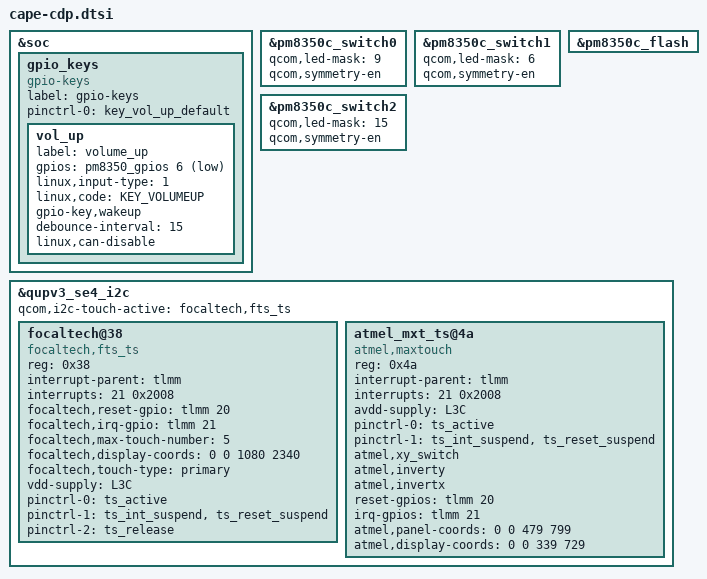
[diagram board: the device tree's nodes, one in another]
#include <dt-bindings/gpio/gpio.h>
#include <dt-bindings/input/input.h>

#include "cape-pmic-overlay.dtsi"

&soc {
	gpio_keys {
		compatible = "gpio-keys";
		label = "gpio-keys";

		pinctrl-names = "default";
		pinctrl-0 = <&key_vol_up_default>;

		vol_up {
			label = "volume_up";
			gpios = <&pm8350_gpios 6 GPIO_ACTIVE_LOW>;
			linux,input-type = <1>;
			linux,code = <KEY_VOLUMEUP>;
			gpio-key,wakeup;
			debounce-interval = <15>;
			linux,can-disable;
		};
	};
};

&pm8350c_switch0 {
	qcom,led-mask = <9>; /* Channels 1 & 4 */
	qcom,symmetry-en;
};

&pm8350c_switch1 {
	qcom,led-mask = <6>; /* Channels 2 & 3 */
	qcom,symmetry-en;
};

&pm8350c_switch2 {
	qcom,led-mask = <15>; /* All Channels */
	qcom,symmetry-en;
};

&pm8350c_flash {
	status = "ok";
};

&qupv3_se4_i2c {
	#address-cells = <1>;
	#size-cells = <0>;

	status = "ok";
	qcom,i2c-touch-active = "focaltech,fts_ts";

	focaltech@38 {
		compatible = "focaltech,fts_ts";
		reg = <0x38>;
		interrupt-parent = <&tlmm>;
		interrupts = <21 0x2008>;
		focaltech,reset-gpio = <&tlmm 20 0x00>;
		focaltech,irq-gpio = <&tlmm 21 0x2008>;
		focaltech,max-touch-number = <5>;
		focaltech,display-coords = <0 0 1080 2340>;
		focaltech,touch-type = "primary";

		vdd-supply = <&L3C>;

		pinctrl-names = "pmx_ts_active", "pmx_ts_suspend","pmx_ts_release";
		pinctrl-0 = <&ts_active>;
		pinctrl-1 = <&ts_int_suspend &ts_reset_suspend>;
		pinctrl-2 = <&ts_release>;
	};

	atmel_mxt_ts@4a {
		compatible = "atmel,maxtouch";
		reg = <0x4a>;
		interrupt-parent = <&tlmm>;
		interrupts = <21 0x2008>;
		avdd-supply = <&L3C>;
		pinctrl-names = "pmx_ts_active", "pmx_ts_suspend";
		pinctrl-0 = <&ts_active>;
		pinctrl-1 = <&ts_int_suspend &ts_reset_suspend>;

		atmel,xy_switch;
		atmel,inverty;
		atmel,invertx;
		reset-gpios = <&tlmm 20 0x00>;
		irq-gpios = <&tlmm 21 0x2008>;
		atmel,panel-coords = <0 0 479 799>;
		atmel,display-coords = <0 0 339 729>;
	};
};
